# PIC16F1829 register map
File version: 1.0
Registers are 8-bit, read-write, reset 0x0 unless marked. A register's access mark holds for its fields unless they carry their own. Offsets are from the block's base; [hi:lo] are bit positions; {n}, {i} and the like mark numbered series; 'fields as' and 'values as' point back to an identical list.

## COMPARATORS
Base 0x00800111
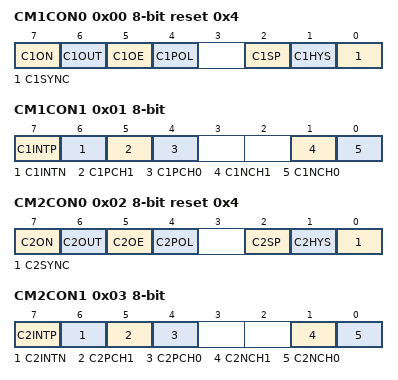
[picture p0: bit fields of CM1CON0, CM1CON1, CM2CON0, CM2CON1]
0x00 CM1CON0 reset 0x4 — CM1CON0, data address 0x111
  [7] C1ON, [6] C1OUT, [5] C1OE, [4] C1POL, [2] C1SP, [1] C1HYS, [0] C1SYNC
0x01 CM1CON1 — CM1CON1, data address 0x112
  [7] C1INTP, [6] C1INTN, [5] C1PCH1, [4] C1PCH0, [1] C1NCH1, [0] C1NCH0
0x02 CM2CON0 reset 0x4 — CM2CON0, data address 0x113
  [7] C2ON, [6] C2OUT, [5] C2OE, [4] C2POL, [2] C2SP, [1] C2HYS, [0] C2SYNC
0x03 CM2CON1 — CM2CON1, data address 0x114
  [7] C2INTP, [6] C2INTN, [5] C2PCH1, [4] C2PCH0, [1] C2NCH1, [0] C2NCH0
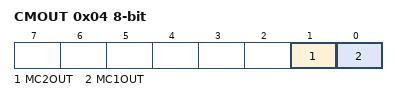
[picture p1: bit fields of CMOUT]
0x04 CMOUT — CMOUT, data address 0x115
  [1] MC2OUT, [0] MC1OUT

## EUSART
Base 0x00800199
0x00 RCREG — RCREG, data address 0x199
0x01 TXREG — TXREG, data address 0x19a
0x02 SPBRGL — SPBRGL, data address 0x19b
0x03 SPBRGH — SPBRGH, data address 0x19c
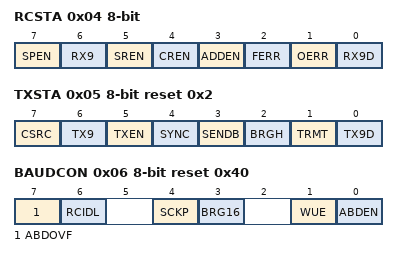
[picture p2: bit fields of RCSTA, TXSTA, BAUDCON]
0x04 RCSTA (reset mask 0xFE) — RCSTA, data address 0x19d
  [7] SPEN, [6] RX9, [5] SREN, [4] CREN, [3] ADDEN, [2] FERR, [1] OERR, [0] RX9D
0x05 TXSTA reset 0x2 — TXSTA, data address 0x19e
  [7] CSRC, [6] TX9, [5] TXEN, [4] SYNC, [3] SENDB, [2] BRGH, [1] TRMT, [0] TX9D
0x06 BAUDCON reset 0x40 — BAUDCON, data address 0x19f
  [7] ABDOVF, [6] RCIDL, [4] SCKP, [3] BRG16, [1] WUE, [0] ABDEN

## INTERRUPTS — Interrupt flags and enables
Base 0x00800011
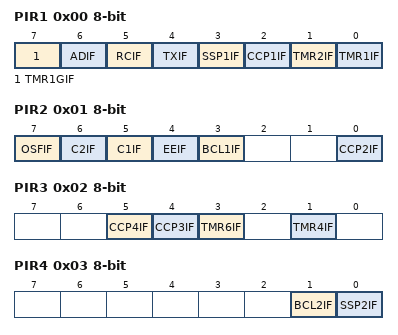
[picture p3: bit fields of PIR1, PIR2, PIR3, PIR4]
0x00 PIR1 — PIR1, data address 0x011
  [7] TMR1GIF, [6] ADIF, [5] RCIF, [4] TXIF, [3] SSP1IF, [2] CCP1IF, [1] TMR2IF, [0] TMR1IF
0x01 PIR2 — PIR2, data address 0x012
  [7] OSFIF, [6] C2IF, [5] C1IF, [4] EEIF, [3] BCL1IF, [0] CCP2IF
0x02 PIR3 — PIR3, data address 0x013
  [5] CCP4IF, [4] CCP3IF, [3] TMR6IF, [1] TMR4IF
0x03 PIR4 — PIR4, data address 0x014
  [1] BCL2IF, [0] SSP2IF
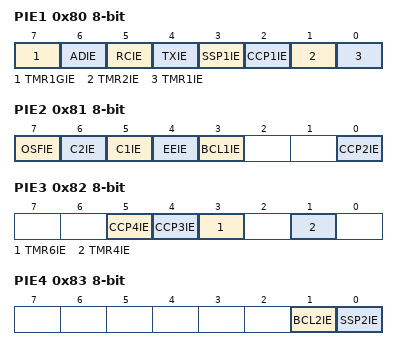
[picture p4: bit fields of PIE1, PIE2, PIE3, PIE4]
0x80 PIE1 — PIE1, data address 0x091
  [7] TMR1GIE, [6] ADIE, [5] RCIE, [4] TXIE, [3] SSP1IE, [2] CCP1IE, [1] TMR2IE, [0] TMR1IE
0x81 PIE2 — PIE2, data address 0x092
  [7] OSFIE, [6] C2IE, [5] C1IE, [4] EEIE, [3] BCL1IE, [0] CCP2IE
0x82 PIE3 — PIE3, data address 0x093
  [5] CCP4IE, [4] CCP3IE, [3] TMR6IE, [1] TMR4IE
0x83 PIE4 — PIE4, data address 0x094
  [1] BCL2IE, [0] SSP2IE

## MSSP — Synchronous serial port
Base 0x00800211
0x00 SSP1BUF reset not defined — SSP1BUF, data address 0x211
  [7:0] SSPBUF
0x01 SSP1ADD — SSP1ADD, data address 0x212
  [7:0] SSPADD
0x02 SSP1MSK reset 0xFF — SSP1MSK, data address 0x213
  [7:0] SSPMSK
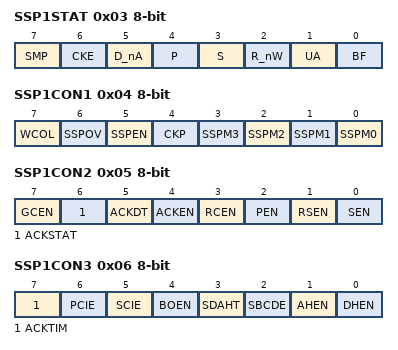
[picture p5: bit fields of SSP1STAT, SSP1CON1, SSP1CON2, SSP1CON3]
0x03 SSP1STAT — SSP1STAT, data address 0x214
  [7] SMP, [6] CKE, [5] D_nA, [4] P, [3] S, [2] R_nW, [1] UA, [0] BF
0x04 SSP1CON1 (reset mask 0xF0) — SSP1CON1, data address 0x215
  [7] WCOL, [6] SSPOV, [5] SSPEN, [4] CKP, [n] SSPM{n} (n=0..3)
0x05 SSP1CON2 — SSP1CON2, data address 0x216
  [7] GCEN, [6] ACKSTAT, [5] ACKDT, [4] ACKEN, [3] RCEN, [2] PEN, [1] RSEN, [0] SEN
0x06 SSP1CON3 — SSP1CON3, data address 0x217
  [7] ACKTIM, [6] PCIE, [5] SCIE, [4] BOEN, [3] SDAHT, [2] SBCDE, [1] AHEN, [0] DHEN
0x08 SSP2BUF reset not defined — SSP2BUF, data address 0x219
  [7:0] SSPBUF
0x09 SSP2ADD — SSP2ADD, data address 0x21a
  [7:0] SSPADD
0x0A SSP2MSK reset 0xFF — SSP2MSK, data address 0x21b
  [7:0] SSPMSK
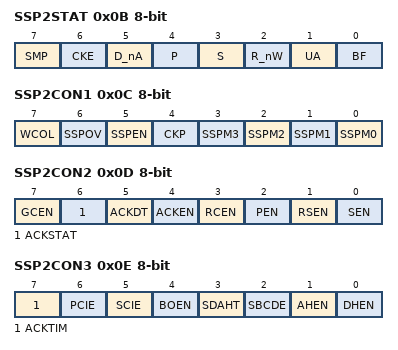
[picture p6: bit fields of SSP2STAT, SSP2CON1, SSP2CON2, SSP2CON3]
0x0B SSP2STAT — SSP2STAT, data address 0x21c
  [7] SMP, [6] CKE, [5] D_nA, [4] P, [3] S, [2] R_nW, [1] UA, [0] BF
0x0C SSP2CON1 (reset mask 0xF0) — SSP2CON1, data address 0x21d
  [7] WCOL, [6] SSPOV, [5] SSPEN, [4] CKP, [n] SSPM{n} (n=0..3)
0x0D SSP2CON2 — SSP2CON2, data address 0x21e
  fields as SSP1CON2
0x0E SSP2CON3 — SSP2CON3, data address 0x21f
  fields as SSP1CON3

## NVM — Flash and EEPROM access
Base 0x00800191
0x00 EEADRL — EEADRL, data address 0x191
0x01 EEADRH reset 0x80 — EEADRH, data address 0x192
  [6:0] EEADRH
0x02 EEDATL reset not defined — EEDATL, data address 0x193
0x03 EEDATH reset not defined — EEDATH, data address 0x194
  [5:0] EEDATH
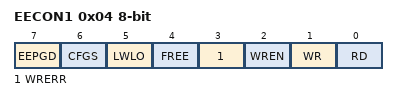
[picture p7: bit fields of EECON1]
0x04 EECON1 (reset mask 0xF7) — EECON1, data address 0x195
  [7] EEPGD, [6] CFGS, [5] LWLO, [4] FREE, [3] WRERR, [2] WREN, [1] WR, [0] RD
0x05 EECON2 reset not defined — EECON2, data address 0x196
